# TC37XPD register map
Vendor: Infineon; Series: ATVMC; File version: 100
CPU: other r0p0, little endian, MPU, FPU, vendor SysTick, 4 interrupt priority bits
Registers are 32-bit, read-write, reset 0x0 unless marked. A register's access mark holds for its fields unless they carry their own. Offsets are from the block's base; [hi:lo] are bit positions; lines under a group give offsets from that group; {n}, {i} and the like mark numbered series; 'fields as' and 'values as' point back to an identical list.

## GTM (part 3 of 13)
Base 0xF0100000
{0x1000+0x800*i} TIM[{i}] (i=0..5) group
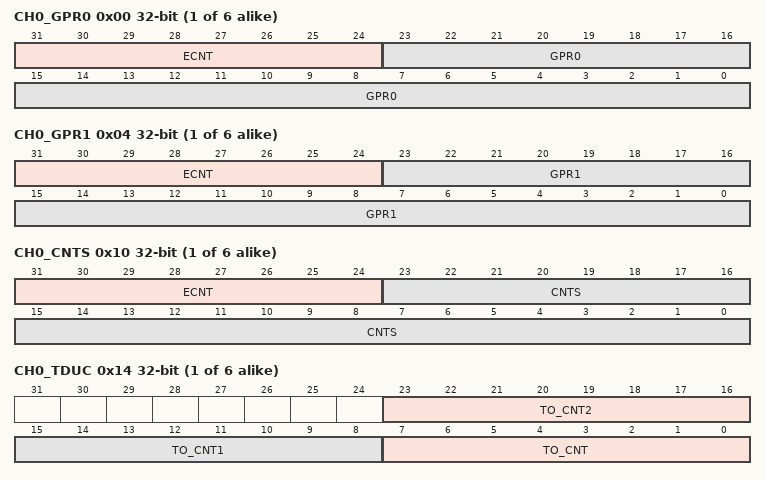
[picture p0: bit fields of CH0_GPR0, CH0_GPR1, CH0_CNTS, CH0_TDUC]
  0x00 CH0_GPR0 access per field — TIM0 Channel 7 General Purpose 0 Register resetvalue={Application Reset:0x0}
    [31:24] ECNT ro — Edge counter. The ECNT counts every incoming filtered edge rising and falling . The counter value is uneven in case of detected rising and even in case of detected falling edge. Thus the input signal level is part of the counter and can be obtained by bit 0 of ECNT .
    [23:0] GPR0 rw — Input signal characteristic parameter 0. The content of this register has different meaning for the TIM channels modes. The content directly depends on the bit fields EGPR0 SEL GPR0 SEL of register TIM i CH x CTRL . Note The content of this register can only be written in TIM channel mode TSSM.
  0x04 CH0_GPR1 access per field — TIM0 Channel 7 General Purpose 1 Register resetvalue={Application Reset:0x0}
    [31:24] ECNT ro — Edge counter. The ECNT counts every incoming filtered edge rising and falling . The counter value is uneven in case of detected rising and even in case of detected falling edge. Thus the input signal level is part of the counter and can be obtained by bit 0 of ECNT .
    [23:0] GPR1 rw — Input signal characteristic parameter 1. The content of this register has different meaning for the TIM channels modes. The content directly depends on the bit fields EGPR1 SEL GPR1 SEL of register TIM i CH x CTRL . In TBCM mode if EGPR1 SEL 1 GPR1 SEL 01 then TIM INP VAL is used as input in all other cases TIM Filter F OUT is used as input and Bits GPR1 23 8 0 The content of this register can only be written in TIM channel mode TGPS and TSSM.
  0x08 CH0_CNT ro — TIM0 Channel 7 SMU Counter Register resetvalue={Application Reset:0x0}
    [23:0] CNT — Actual SMU counter value. The meaning of this value depends on the configured mode TPWM actual duration of PWM signal.TPIM actual duration of all pulses sum of pulses .TIEM actual number of received edges.TIPM actual number of received edges.TGPS elapsed time for periodic sampling.TSSM shift data.
  0x0C CH0_ECNT ro — TIM0 Channel 7 SMU Edge Counter Register resetvalue={Application Reset:0x0}
    [15:0] ECNT — Edge counter. If TIM channel is disabled the content of ECNT gets frozen. A read will auto clear the bits 15 1 . Further read accesses to ECNT will show on Bit 0 the actual input signal value of the channel.
  0x10 CH0_CNTS access per field — TIM0 Channel 7 SMU Shadow Counter Register resetvalue={Application Reset:0x0}
    [31:24] ECNT ro — Edge counter ECNT. The ECNT counts every incoming filtered edge rising and falling . The counter value is uneven in case of detected rising and even in case of detected falling edge. Thus the input signal level is part of the counter and can be obtained by bit 0 of ECNT .
    [23:0] CNTS rw — Counter shadow register. The content of this register has different meaning for the TIM channels modes. The content depends directly on the bit field CNTS SEL of register TIM i CH x CTRL . The register TIM i CH x CNTS is only writable in TIPM TBCM TGPS and TSSM mode.
  0x14 CH0_TDUC — TIM0 Channel 7 TDU Counter Register resetvalue={Application Reset:0x0}
    [23:16] TO_CNT2 — Current Timeout value slice2 for channel x. Counter will be reset to 0x0 on TDU RESYNC condition.
    [15:8] TO_CNT1 — Current Timeout value slice1 for channel x. Counter will be reset to 0x0 on TDU RESYNC condition.
    [7:0] TO_CNT — Current Timeout value slice0 for channel x. SLICING 0b11 counter will be reset to 0X0 on TDU RESYNC condition. SLICING 0b11 counter will be loaded with TOV2 on TDU RESYNC condition.
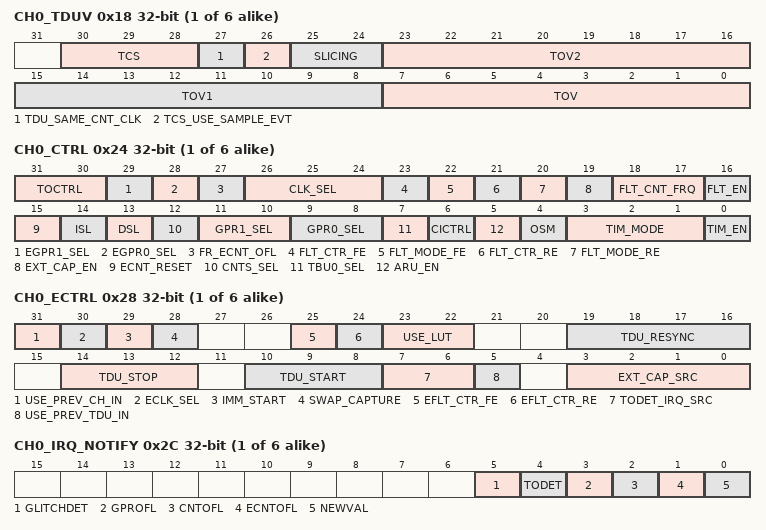
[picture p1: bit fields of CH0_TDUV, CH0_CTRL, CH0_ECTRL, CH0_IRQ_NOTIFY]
  0x18 CH0_TDUV — TIM0 Channel 7 TDU Control Register resetvalue={Application Reset:0x0}
    [30:28] TCS — Timeout Clock selection
    [27] TDU_SAME_CNT_CLK — Define clocking of TO CNT TO CNT1
    [26] TCS_USE_SAMPLE_EVT — Use tdu sample evt as Timeout Clock
    [25:24] SLICING — Cascading of counter slices. If USE LUT 0b00 USE LUT 0b00
    [23:16] TOV2 — Time out compare value slice2 for channel x. SLICING 0b11 Compare value for TO CNT2. SLICING 0b11 TOV2 operate as a shadow register for TO CNT.
    [15:8] TOV1 — Time out compare value slice1 for channel x. Compare value for TO CNT1.
    [7:0] TOV — Time out compare value slice0 for channel x. Compare value for TO CNT.
  0x1C CH0_FLT_RE — TIM0 Channel 7 Filter Parameter 0 Register resetvalue={Application Reset:0x0}
    [23:0] FLT_RE — Filter parameter for rising edge. FLT RE has different meanings in the various filter modes.Immediate edge propagation mode acceptance time for rising edgeIndividual deglitch time mode deglitch time for rising edge.
  0x20 CH0_FLT_FE — TIM0 Channel 7 Filter Parameter 1 Register resetvalue={Application Reset:0x0}
    [23:0] FLT_FE — Filter parameter for falling edge. FLT FE has different meanings in the various filter modes.Immediate edge propagation mode acceptance time for falling edge Individual deglitch time mode deglitch time for falling edge.
  0x24 CH0_CTRL — TIM0 Channel 7 Control Register resetvalue={Application Reset:0x0}
    [31:30] TOCTRL — Timeout control. It has to be mentioned that writing of TOCTRL 0 will every time stop the TDU independent of the previous state of TOCTRL.
    [29] EGPR1_SEL — Extension of GPR1 SEL bit field. Details described in GPR1 SEL bit field.
    [28] EGPR0_SEL — Extension of GPR0 SEL bit field. Details described in GPR0 SEL bit field.
    [27] FR_ECNT_OFL — Extended Edge counter overflow behavior
    [26:24] CLK_SEL — CMU clock source select for channel. If ECLK SEL 0 ECLK SEL 1
    [23] FLT_CTR_FE — Filter counter mode for falling edge. Coding see CROSSREFERENCE . Coding see Family Spec.
    [22] FLT_MODE_FE — Filter mode for falling edge. Coding see CROSSREFERENCE . Coding see Family Spec.
    [21] FLT_CTR_RE — Filter counter mode for rising edge. Coding see CROSSREFERENCE . Coding see Family Spec.
    [20] FLT_MODE_RE — Filter mode for rising edge. Coding see CROSSREFERENCE . Coding see Family Spec.
    [19] EXT_CAP_EN — Enables external capture mode. The selected TIM mode is only sensitive to external capture pulses the input event changes are ignored.
    [18:17] FLT_CNT_FRQ — Filter counter frequency select
    [16] FLT_EN — Filter enable for channel x. If the filter is disabled all filter related units including CSU are bypassed which means that the signal F IN is directly routed to signal F OUT .
    [15] ECNT_RESET — Enables resetting of counter in certain modes. If TIM MODE 0b101 TGPS TIM MODE 0b000 TPWM else ECNT counter operating in wrap around mode In TIM MODE 0b110 TSSM the bit field ECNT RESET defines the initial polarity for the shift register.
    [14] ISL — Ignore signal level. This bit is mode dependent and will have different meanings see details in the TIM Channel mode description .
    [13] DSL — Signal level control. In TIM MODE 0b110 TSSM the bit field DSL defines the shift direction. 0 B 160 160 160 160 160 Shift left 1 B 160 160 160 160 160 Shift right
    [12] CNTS_SEL — Selection for CNTS register. The functionality of the CNTS SEL is disabled in the modes TIPM TGPS and TBCM. CNTS SEL in TSSM mode selects the source signal for registered or latched shift out operation. 0 B 160 160 160 160 160 use F OUTx 1 B 160 160 160 160 160 use TIM INx
    [11:10] GPR1_SEL — Selection for GPR1 register. If EGPR1 SEL 0 EGPR1 SEL 1 If a reserved value is written to the EGPR1 SEL GPR1 SEL bit fields the hardware will use TBU TS0 input. Note In TBCM mode EGPR1 SEL 1 GPR1 SEL 01 selects TIM INP VAL as input in all other cases TIM Filter F OUT is used.
    [9:8] GPR0_SEL — Selection for GPR0 register. If EGPR0 SEL 0 EGPR0 SEL 1 If a reserved value is written to the EGPR0 SEL GPR0 SEL bit fields the hardware will use TBU TS0 input.
    [7] TBU0_SEL — TBU TS0 bits input select for TIM0 CH x GPRz z 0 1 . This bit is only applicable for TIM0.
    [6] CICTRL — Channel Input Control
    [5] ARU_EN — GPR0 and GPR1 register values routed to ARU
    [4] OSM — One shot mode. After finishing the action in one shot mode the TIM EN bit is cleared automatically.
    [3:1] TIM_MODE — TIM channel x mode. If an undefined value is written to the TIM MODE register the hardware switches automatically to TIM MODE 0b000 TPWM mode . The TIM MODE register should not be changed while the TIM channel is enabled. If the TIM channel is enabled and operating in TPWM or TPIM mode after the first valid edge defined by DSL has occurred a reconfiguration of DSL ISL TIM MODE will not change the channel behavior. Reading these bit fields after reconfiguration will show the newly configured settings but the initial channel behavior will not change. Only a disabling of the TIM channel by setting TIM EN 0 and reenabling with TIM EN 1 will change the channel operation mode.
    [0] TIM_EN — TIM channel x enable. Enabling of the channel resets the registers ECNT TIM i CH x CNT TIM i CH x GPR0 and TIM i CH x GPR1 to their reset values. After finishing the action in one shot mode the TIM EN bit is cleared automatically. Otherwise the bit must be cleared manually.
  0x28 CH0_ECTRL — TIM0 Channel 7 Extended Control Register resetvalue={Application Reset:0x0}
    [31] USE_PREV_CH_IN — Select input data source for TIM channel
    [30] ECLK_SEL — Extension of bit field CLK SEL. Details described in CLK SEL bit field of register TIM i CH x CTRL.
    [29] IMM_START — Start immediately the measurement. This bit is only applicable in TPWM and TPIM mode. Set to 0 in all other modes.
    [28] SWAP_CAPTURE — Swap point of time of capturing CNTS and GPR1. This bit is only applicable in TPWM and TPIM mode. Set to 0 in all other modes.
    [25] EFLT_CTR_FE — Extension of bit field FLT CTR FE. Details described in FLT CTR FE bit field of register TIM i CH x CTRL.
    [24] EFLT_CTR_RE — Extension of bit field FLT CTR RE. Details described in FLT CTR RE bit field of register TIM i CH x CTRL.
    [23:22] USE_LUT — Generate Filter input by lookup table
    [19:16] TDU_RESYNC — Defines condition which will resynchronize the TDU unit. Encoding see Table 160 14 and Table 160 15 .
    [14:12] TDU_STOP — Defines condition which will stop the TDU unit. Note tdu toctrl 0 event is defined as Each writing of TOCTRL 0 independent of current TOCTRL while TDU is started. This event will last 1 system clock cycle.
    [10:8] TDU_START — Defines condition which will start the TDU unit. In mode SLICING 0b11 every start restart will load the TO CNT with value TOV2. Note tdu start 000 event is defined as Each writing of TOCTRL 0 independent of current TOCTRL while TDU START 0b000 and TDU is stopped initially or stopped by TDU STOP event . This event will last 1 system clock cycle.
    [7:6] TODET_IRQ_SRC — selection of source for TODET IRQ. With TODET IRQ SRC 0b00 the ACB bit 2 will be driven by signal tdu timeout evt if TODET IRQ SRC 0b00 ACB2 will be 0.
    [5] USE_PREV_TDU_IN — Select input data source for TDU
    [3:0] EXT_CAP_SRC — Defines selected source for triggering the EXT CAPTURE functionality
  0x2C CH0_IRQ_NOTIFY — TIM0 Channel 7 Interrupt Notification Register resetvalue={Application Reset:0x0}
    [5] GLITCHDET — Glitch detected on channel x x 0...m 1 . This bit will be cleared on a CPU write access of value 1 . A read access leaves the bit unchanged.
    [4] TODET — Timeout reached for input signal of channel x. See bit 0.
    [3] GPROFL — GPR0 and GPR1 data overflow. Old data not read out before new data has arrived at input pin. See bit 0.
    [2] CNTOFL — SMU CNT counter overflow of channel x. See bit 0.
    [1] ECNTOFL — counter overflow of channel x. See bit 0.
    [0] NEWVAL — New measurement value detected by in channel x. This bit will be cleared on a CPU write access of value 1 . A read access leaves the bit unchanged.
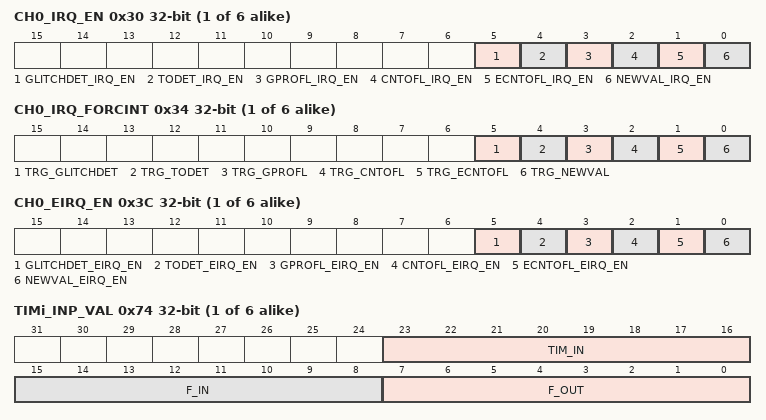
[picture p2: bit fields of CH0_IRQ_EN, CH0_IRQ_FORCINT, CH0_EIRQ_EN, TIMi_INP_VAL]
  0x30 CH0_IRQ_EN — TIM0 Channel 7 Interrupt Enable Register resetvalue={Application Reset:0x0}
    [5] GLITCHDET_IRQ_EN — TIM GLITCHDETx IRQ interrupt enable. Coding see bit 0.
    [4] TODET_IRQ_EN — TIM TODETx IRQ interrupt enable. Coding see bit 0.
    [3] GPROFL_IRQ_EN — TIM GPROFL IRQ interrupt enable. Coding see bit 0.
    [2] CNTOFL_IRQ_EN — TIM CNTOFLx IRQ interrupt enable. Coding see bit 0.
    [1] ECNTOFL_IRQ_EN — TIM ECNTOFLx IRQ interrupt enable. Coding see bit 0.
    [0] NEWVAL_IRQ_EN — TIM NEWVALx IRQ interrupt enable
  0x34 CH0_IRQ_FORCINT — TIM0 Channel 7 Force Interrupt Register resetvalue={Application Reset:0x0}
    [5] TRG_GLITCHDET — Trigger GLITCHDET bit in TIM CHx IRQ NOTIFY register by software. Coding see bit 0.
    [4] TRG_TODET — Trigger TODET bit in TIM CHx IRQ NOTIFY register by software. Coding see bit 0.
    [3] TRG_GPROFL — Trigger GPROFL bit in TIM CHx IRQ NOTIFY register by software. Coding see bit 0.
    [2] TRG_CNTOFL — Trigger CNTOFL bit in TIM CHx IRQ NOTIFY register by software. Coding see bit 0.
    [1] TRG_ECNTOFL — Trigger ECNTOFL bit in TIM CHx IRQ NOTIFY register by software. Coding see bit 0.
    [0] TRG_NEWVAL — Trigger NEWVAL bit in TIM CHx IRQ NOTIFY register by software. This bit is cleared automatically after write. This bit is write protected by bit RF PROT of register GTM CTRL.
  0x38 CH0_IRQ_MODE — TIM0 Channel 7 Interrupt Mode Configuration Register resetvalue={Application Reset:0x0}
    [1:0] IRQ_MODE — IRQ mode selection. The interrupt modes are described in CROSSREFERENCE .
  0x3C CH0_EIRQ_EN — TIM0 Channel 7 Error Interrupt Enable Register resetvalue={Application Reset:0x0}
    [5] GLITCHDET_EIRQ_EN — TIM GLITCHDETx IRQ interrupt enable. Coding see bit 0.
    [4] TODET_EIRQ_EN — TIM TODETx IRQ interrupt enable. Coding see bit 0.
    [3] GPROFL_EIRQ_EN — TIM GPROFL IRQ interrupt enable. Coding see bit 0.
    [2] CNTOFL_EIRQ_EN — TIM CNTOFLx IRQ interrupt enable. Coding see bit 0.
    [1] ECNTOFL_EIRQ_EN — TIM ECNTOFLx IRQ interrupt enable. Coding see bit 0.
    [0] NEWVAL_EIRQ_EN — TIM NEWVALx EIRQ error interrupt enable
  0x74 TIMi_INP_VAL ro — TIM0 Input Value Observation Register resetvalue={Application Reset:0x0}
    [23:16] TIM_IN — Signals after TIM input signal synchronization
    [15:8] F_IN — Signals after INPSRC selection before TIM FLT unit
    [7:0] F_OUT — Signals after TIM FLT unit
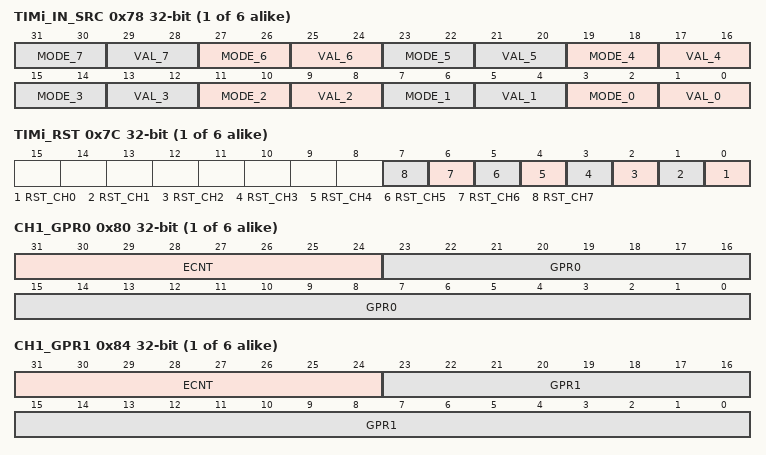
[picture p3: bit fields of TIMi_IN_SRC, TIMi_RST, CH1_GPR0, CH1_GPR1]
  0x78 TIMi_IN_SRC — TIM0 AUX IN Source Selection Register resetvalue={Application Reset:0x0}
    [4n+3:4n+2] MODE_{n} (n=0..7) — Input source to Channel 7. Multicore encoding in use MODE x 1 defines the state of the signal . Function table MODE x 1 0 VAL x 1 0 160 160 160 160 The input signal defined by bit field CICTRL of the TIM channel is used 160 160 160 160 as input source. MODE x 1 0 VAL x 1 1 160 160 160 160 The signal TIM AUX IN of the TIM channel is used as input source. MODE x 1 1 160 160 160 160 The state VAL x 1 defines the input level for the TIM channel. Any read access to a MODE x bit field will always result in a value 00 or 11 indicating current state. A modification of the state is only performed with the values 01 and 10. Writing the values 00 and 11 is always ignored.
    [4n+1:4n] VAL_{n} (n=0..7) — Value to be fed to Channel 7. Multicore encoding in use VAL x 1 defines the state of the signal . Function depends on the combination of VAL x 1 and MODE x 1 see MODE 0 description. Any read access to a VAL x bit field will always result in a value 00 or 11 indicating current state. A modification of the state is only performed with the values 01 and 10. Writing the values 00 and 11 is always ignored.
  0x7C TIMi_RST — TIM0 Global Software Reset Register resetvalue={Application Reset:0x0}
    [n] RST_CH{n} (n=0..7) — Software reset of channel 7. This bit is cleared automatically after write by CPU. The channel registers are set to their reset values and channel operation is stopped immediately. Please note that the RST field width of this register depends on the number of implemented channels m within this sub module. This register description represents a register layout for m 8.
  0x80 CH1_GPR0 access per field — TIM0 Channel 7 General Purpose 0 Register resetvalue={Application Reset:0x0}
    fields as TIM[0].CH0_GPR0
  0x84 CH1_GPR1 access per field — TIM0 Channel 7 General Purpose 1 Register resetvalue={Application Reset:0x0}
    fields as TIM[0].CH0_GPR1
  0x88 CH1_CNT ro — TIM0 Channel 7 SMU Counter Register resetvalue={Application Reset:0x0}
    fields as TIM[0].CH0_CNT
  0x8C CH1_ECNT ro — TIM0 Channel 7 SMU Edge Counter Register resetvalue={Application Reset:0x0}
    fields as TIM[0].CH0_ECNT
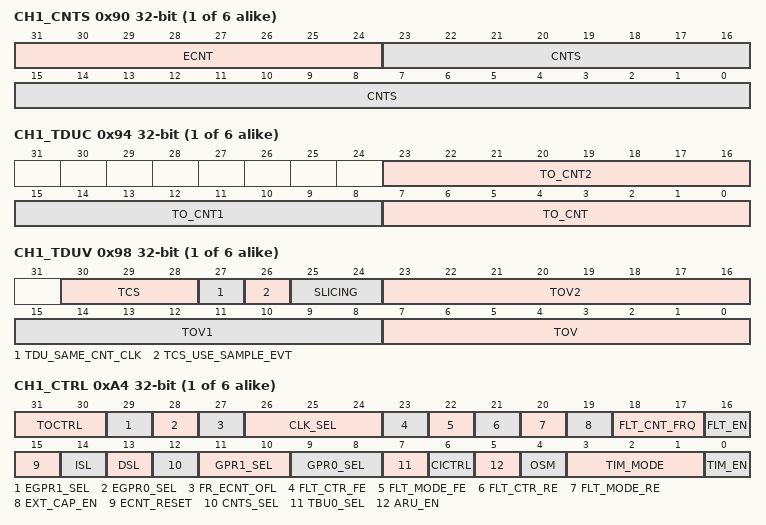
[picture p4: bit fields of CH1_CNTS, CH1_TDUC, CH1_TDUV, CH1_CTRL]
  0x90 CH1_CNTS access per field — TIM0 Channel 7 SMU Shadow Counter Register resetvalue={Application Reset:0x0}
    fields as TIM[0].CH0_CNTS
  0x94 CH1_TDUC — TIM0 Channel 7 TDU Counter Register resetvalue={Application Reset:0x0}
    fields as TIM[0].CH0_TDUC
  0x98 CH1_TDUV — TIM0 Channel 7 TDU Control Register resetvalue={Application Reset:0x0}
    fields as TIM[0].CH0_TDUV
  0x9C CH1_FLT_RE — TIM0 Channel 7 Filter Parameter 0 Register resetvalue={Application Reset:0x0}
    fields as TIM[0].CH0_FLT_RE
  0xA0 CH1_FLT_FE — TIM0 Channel 7 Filter Parameter 1 Register resetvalue={Application Reset:0x0}
    fields as TIM[0].CH0_FLT_FE
  0xA4 CH1_CTRL — TIM0 Channel 7 Control Register resetvalue={Application Reset:0x0}
    fields as TIM[0].CH0_CTRL
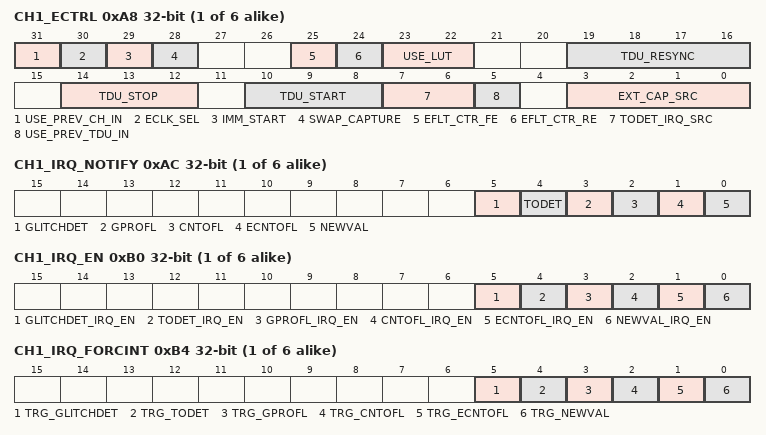
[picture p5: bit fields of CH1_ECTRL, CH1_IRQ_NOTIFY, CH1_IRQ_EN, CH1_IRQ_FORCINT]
  0xA8 CH1_ECTRL — TIM0 Channel 7 Extended Control Register resetvalue={Application Reset:0x0}
    fields as TIM[0].CH0_ECTRL
  0xAC CH1_IRQ_NOTIFY — TIM0 Channel 7 Interrupt Notification Register resetvalue={Application Reset:0x0}
    fields as TIM[0].CH0_IRQ_NOTIFY
  0xB0 CH1_IRQ_EN — TIM0 Channel 7 Interrupt Enable Register resetvalue={Application Reset:0x0}
    fields as TIM[0].CH0_IRQ_EN
  0xB4 CH1_IRQ_FORCINT — TIM0 Channel 7 Force Interrupt Register resetvalue={Application Reset:0x0}
    fields as TIM[0].CH0_IRQ_FORCINT
  0xB8 CH1_IRQ_MODE — TIM0 Channel 7 Interrupt Mode Configuration Register resetvalue={Application Reset:0x0}
    fields as TIM[0].CH0_IRQ_MODE
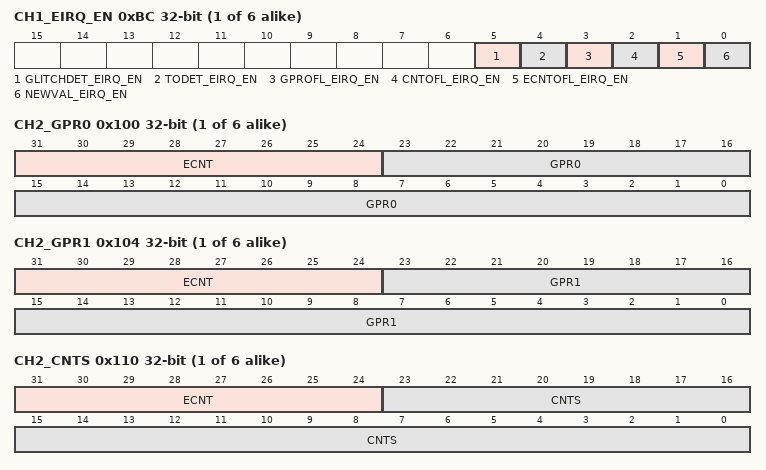
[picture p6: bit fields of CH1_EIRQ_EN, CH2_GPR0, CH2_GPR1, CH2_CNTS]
  0xBC CH1_EIRQ_EN — TIM0 Channel 7 Error Interrupt Enable Register resetvalue={Application Reset:0x0}
    fields as TIM[0].CH0_EIRQ_EN
  0x100 CH2_GPR0 access per field — TIM0 Channel 7 General Purpose 0 Register resetvalue={Application Reset:0x0}
    fields as TIM[0].CH0_GPR0
  0x104 CH2_GPR1 access per field — TIM0 Channel 7 General Purpose 1 Register resetvalue={Application Reset:0x0}
    fields as TIM[0].CH0_GPR1
  0x108 CH2_CNT ro — TIM0 Channel 7 SMU Counter Register resetvalue={Application Reset:0x0}
    fields as TIM[0].CH0_CNT
  0x10C CH2_ECNT ro — TIM0 Channel 7 SMU Edge Counter Register resetvalue={Application Reset:0x0}
    fields as TIM[0].CH0_ECNT
  0x110 CH2_CNTS access per field — TIM0 Channel 7 SMU Shadow Counter Register resetvalue={Application Reset:0x0}
    fields as TIM[0].CH0_CNTS
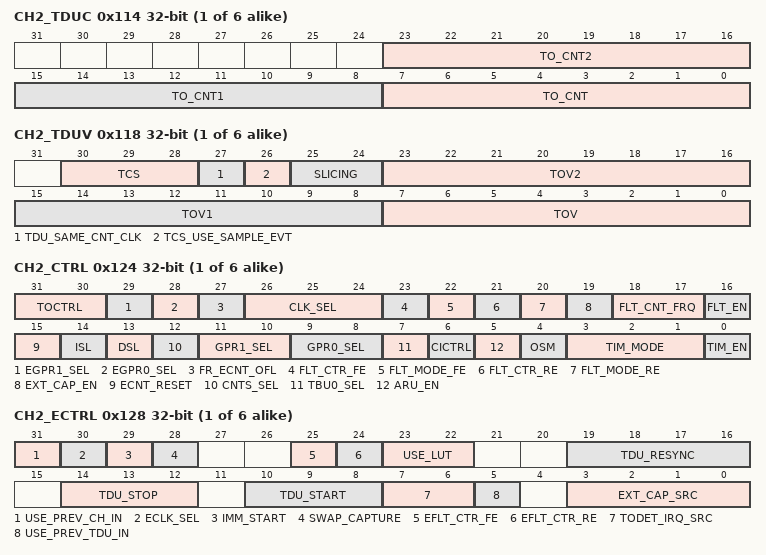
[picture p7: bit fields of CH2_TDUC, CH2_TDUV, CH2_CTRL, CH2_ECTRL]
  0x114 CH2_TDUC — TIM0 Channel 7 TDU Counter Register resetvalue={Application Reset:0x0}
    fields as TIM[0].CH0_TDUC
  0x118 CH2_TDUV — TIM0 Channel 7 TDU Control Register resetvalue={Application Reset:0x0}
    fields as TIM[0].CH0_TDUV
  0x11C CH2_FLT_RE — TIM0 Channel 7 Filter Parameter 0 Register resetvalue={Application Reset:0x0}
    fields as TIM[0].CH0_FLT_RE
  0x120 CH2_FLT_FE — TIM0 Channel 7 Filter Parameter 1 Register resetvalue={Application Reset:0x0}
    fields as TIM[0].CH0_FLT_FE
  0x124 CH2_CTRL — TIM0 Channel 7 Control Register resetvalue={Application Reset:0x0}
    fields as TIM[0].CH0_CTRL
  0x128 CH2_ECTRL — TIM0 Channel 7 Extended Control Register resetvalue={Application Reset:0x0}
    fields as TIM[0].CH0_ECTRL
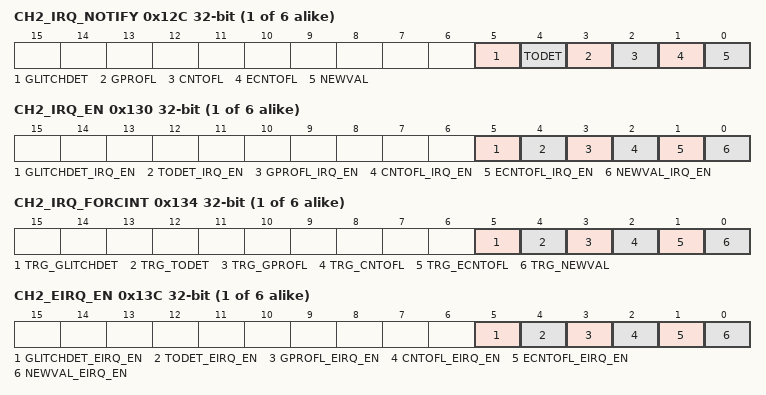
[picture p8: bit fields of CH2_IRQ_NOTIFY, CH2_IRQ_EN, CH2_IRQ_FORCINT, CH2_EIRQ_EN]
  0x12C CH2_IRQ_NOTIFY — TIM0 Channel 7 Interrupt Notification Register resetvalue={Application Reset:0x0}
    fields as TIM[0].CH0_IRQ_NOTIFY
  0x130 CH2_IRQ_EN — TIM0 Channel 7 Interrupt Enable Register resetvalue={Application Reset:0x0}
    fields as TIM[0].CH0_IRQ_EN
  0x134 CH2_IRQ_FORCINT — TIM0 Channel 7 Force Interrupt Register resetvalue={Application Reset:0x0}
    fields as TIM[0].CH0_IRQ_FORCINT
  0x138 CH2_IRQ_MODE — TIM0 Channel 7 Interrupt Mode Configuration Register resetvalue={Application Reset:0x0}
    fields as TIM[0].CH0_IRQ_MODE
  0x13C CH2_EIRQ_EN — TIM0 Channel 7 Error Interrupt Enable Register resetvalue={Application Reset:0x0}
    fields as TIM[0].CH0_EIRQ_EN
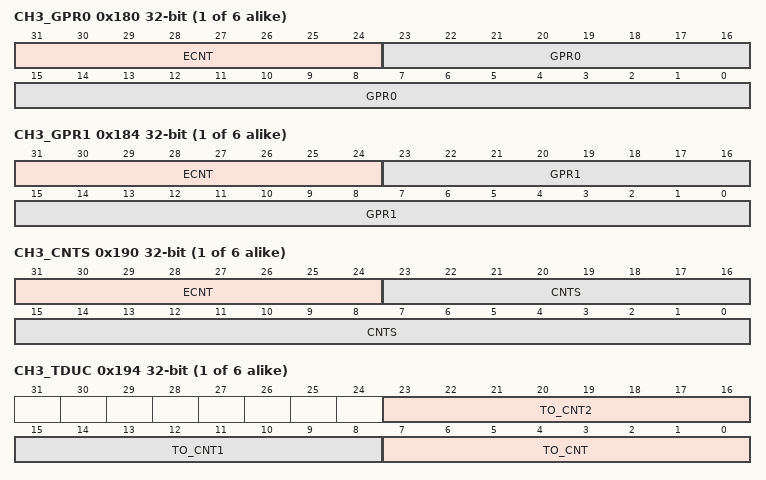
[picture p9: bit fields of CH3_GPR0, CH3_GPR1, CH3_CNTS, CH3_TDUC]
  0x180 CH3_GPR0 access per field — TIM0 Channel 7 General Purpose 0 Register resetvalue={Application Reset:0x0}
    fields as TIM[0].CH0_GPR0
  0x184 CH3_GPR1 access per field — TIM0 Channel 7 General Purpose 1 Register resetvalue={Application Reset:0x0}
    fields as TIM[0].CH0_GPR1
  0x188 CH3_CNT ro — TIM0 Channel 7 SMU Counter Register resetvalue={Application Reset:0x0}
    fields as TIM[0].CH0_CNT
  0x18C CH3_ECNT ro — TIM0 Channel 7 SMU Edge Counter Register resetvalue={Application Reset:0x0}
    fields as TIM[0].CH0_ECNT
  0x190 CH3_CNTS access per field — TIM0 Channel 7 SMU Shadow Counter Register resetvalue={Application Reset:0x0}
    fields as TIM[0].CH0_CNTS
  0x194 CH3_TDUC — TIM0 Channel 7 TDU Counter Register resetvalue={Application Reset:0x0}
    fields as TIM[0].CH0_TDUC
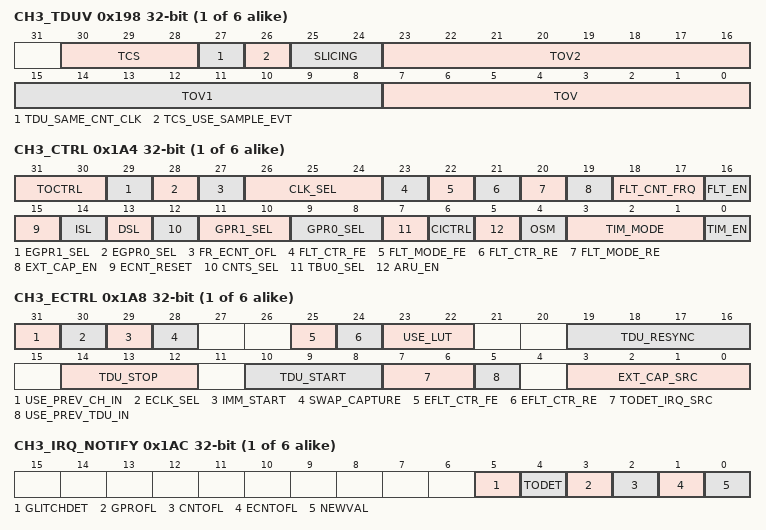
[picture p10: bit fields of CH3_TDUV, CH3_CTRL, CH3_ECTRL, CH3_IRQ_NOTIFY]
  0x198 CH3_TDUV — TIM0 Channel 7 TDU Control Register resetvalue={Application Reset:0x0}
    fields as TIM[0].CH0_TDUV
  0x19C CH3_FLT_RE — TIM0 Channel 7 Filter Parameter 0 Register resetvalue={Application Reset:0x0}
    fields as TIM[0].CH0_FLT_RE
  0x1A0 CH3_FLT_FE — TIM0 Channel 7 Filter Parameter 1 Register resetvalue={Application Reset:0x0}
    fields as TIM[0].CH0_FLT_FE
  0x1A4 CH3_CTRL — TIM0 Channel 7 Control Register resetvalue={Application Reset:0x0}
    fields as TIM[0].CH0_CTRL
  0x1A8 CH3_ECTRL — TIM0 Channel 7 Extended Control Register resetvalue={Application Reset:0x0}
    fields as TIM[0].CH0_ECTRL
  0x1AC CH3_IRQ_NOTIFY — TIM0 Channel 7 Interrupt Notification Register resetvalue={Application Reset:0x0}
    fields as TIM[0].CH0_IRQ_NOTIFY
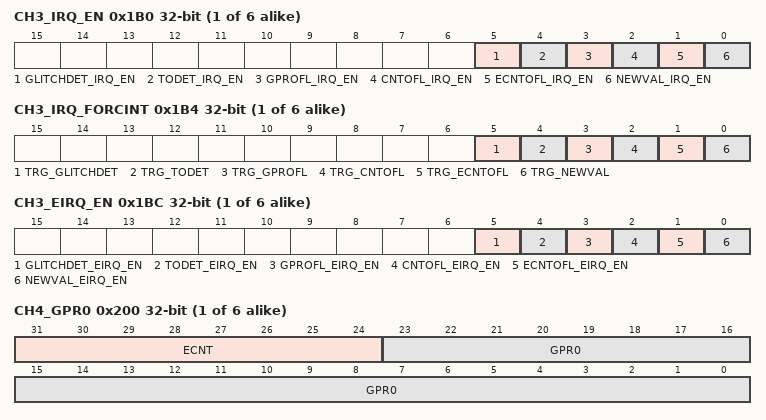
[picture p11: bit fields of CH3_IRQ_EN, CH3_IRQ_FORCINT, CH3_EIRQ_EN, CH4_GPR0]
  0x1B0 CH3_IRQ_EN — TIM0 Channel 7 Interrupt Enable Register resetvalue={Application Reset:0x0}
    fields as TIM[0].CH0_IRQ_EN
  0x1B4 CH3_IRQ_FORCINT — TIM0 Channel 7 Force Interrupt Register resetvalue={Application Reset:0x0}
    fields as TIM[0].CH0_IRQ_FORCINT
  0x1B8 CH3_IRQ_MODE — TIM0 Channel 7 Interrupt Mode Configuration Register resetvalue={Application Reset:0x0}
    fields as TIM[0].CH0_IRQ_MODE
  0x1BC CH3_EIRQ_EN — TIM0 Channel 7 Error Interrupt Enable Register resetvalue={Application Reset:0x0}
    fields as TIM[0].CH0_EIRQ_EN
  0x200 CH4_GPR0 access per field — TIM0 Channel 7 General Purpose 0 Register resetvalue={Application Reset:0x0}
    fields as TIM[0].CH0_GPR0
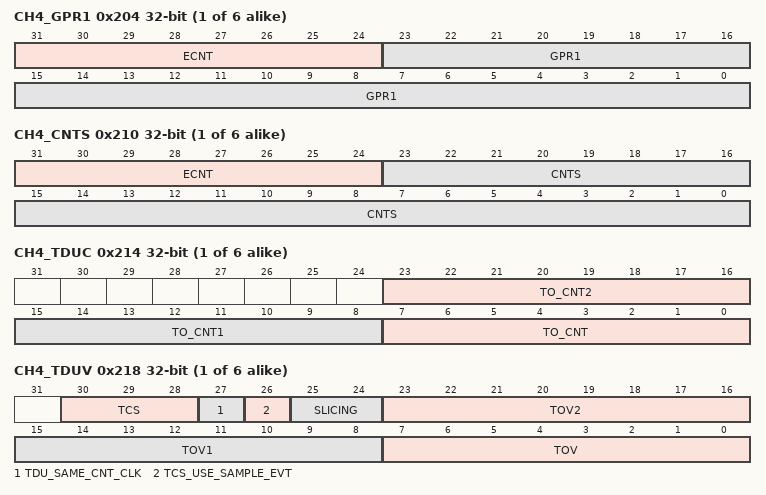
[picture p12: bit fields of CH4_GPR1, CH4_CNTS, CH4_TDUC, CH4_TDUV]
  0x204 CH4_GPR1 access per field — TIM0 Channel 7 General Purpose 1 Register resetvalue={Application Reset:0x0}
    fields as TIM[0].CH0_GPR1
  0x208 CH4_CNT ro — TIM0 Channel 7 SMU Counter Register resetvalue={Application Reset:0x0}
    fields as TIM[0].CH0_CNT
  0x20C CH4_ECNT ro — TIM0 Channel 7 SMU Edge Counter Register resetvalue={Application Reset:0x0}
    fields as TIM[0].CH0_ECNT
  0x210 CH4_CNTS access per field — TIM0 Channel 7 SMU Shadow Counter Register resetvalue={Application Reset:0x0}
    fields as TIM[0].CH0_CNTS
  0x214 CH4_TDUC — TIM0 Channel 7 TDU Counter Register resetvalue={Application Reset:0x0}
    fields as TIM[0].CH0_TDUC
  0x218 CH4_TDUV — TIM0 Channel 7 TDU Control Register resetvalue={Application Reset:0x0}
    fields as TIM[0].CH0_TDUV
  0x21C CH4_FLT_RE — TIM0 Channel 7 Filter Parameter 0 Register resetvalue={Application Reset:0x0}
    fields as TIM[0].CH0_FLT_RE
  0x220 CH4_FLT_FE — TIM0 Channel 7 Filter Parameter 1 Register resetvalue={Application Reset:0x0}
    fields as TIM[0].CH0_FLT_FE
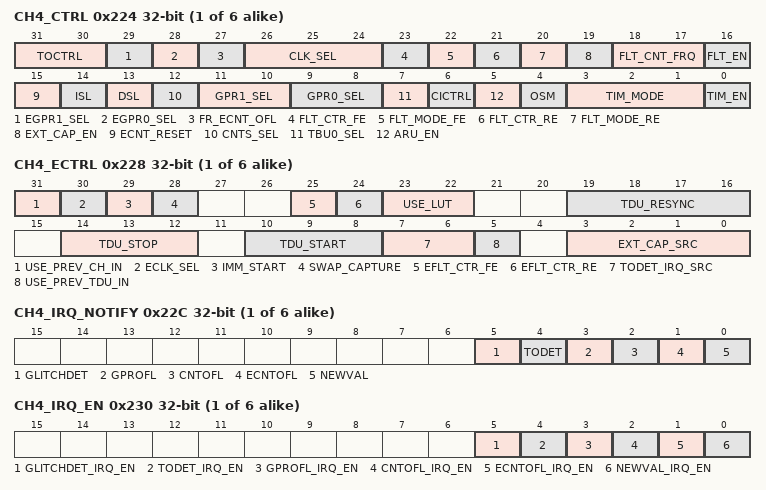
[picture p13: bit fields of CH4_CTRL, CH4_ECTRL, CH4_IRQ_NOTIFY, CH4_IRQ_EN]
  0x224 CH4_CTRL — TIM0 Channel 7 Control Register resetvalue={Application Reset:0x0}
    fields as TIM[0].CH0_CTRL
  0x228 CH4_ECTRL — TIM0 Channel 7 Extended Control Register resetvalue={Application Reset:0x0}
    fields as TIM[0].CH0_ECTRL
  0x22C CH4_IRQ_NOTIFY — TIM0 Channel 7 Interrupt Notification Register resetvalue={Application Reset:0x0}
    fields as TIM[0].CH0_IRQ_NOTIFY
  0x230 CH4_IRQ_EN — TIM0 Channel 7 Interrupt Enable Register resetvalue={Application Reset:0x0}
    fields as TIM[0].CH0_IRQ_EN
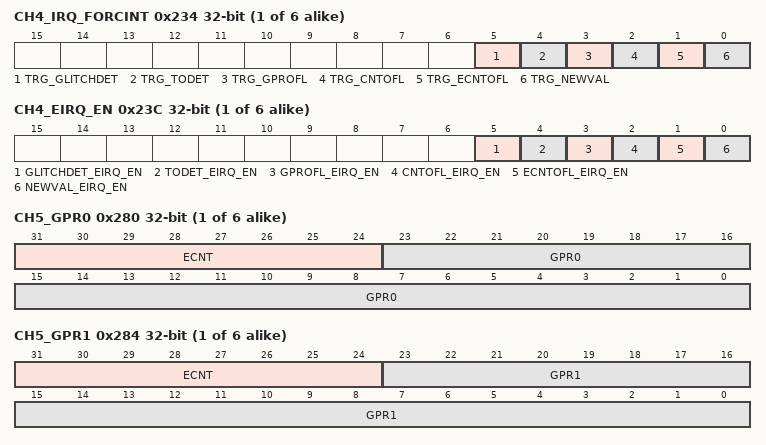
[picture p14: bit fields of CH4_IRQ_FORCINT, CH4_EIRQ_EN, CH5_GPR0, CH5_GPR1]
  0x234 CH4_IRQ_FORCINT — TIM0 Channel 7 Force Interrupt Register resetvalue={Application Reset:0x0}
    fields as TIM[0].CH0_IRQ_FORCINT
  0x238 CH4_IRQ_MODE — TIM0 Channel 7 Interrupt Mode Configuration Register resetvalue={Application Reset:0x0}
    fields as TIM[0].CH0_IRQ_MODE
  0x23C CH4_EIRQ_EN — TIM0 Channel 7 Error Interrupt Enable Register resetvalue={Application Reset:0x0}
    fields as TIM[0].CH0_EIRQ_EN
  0x280 CH5_GPR0 access per field — TIM0 Channel 7 General Purpose 0 Register resetvalue={Application Reset:0x0}
    fields as TIM[0].CH0_GPR0
  0x284 CH5_GPR1 access per field — TIM0 Channel 7 General Purpose 1 Register resetvalue={Application Reset:0x0}
    fields as TIM[0].CH0_GPR1
  0x288 CH5_CNT ro — TIM0 Channel 7 SMU Counter Register resetvalue={Application Reset:0x0}
    fields as TIM[0].CH0_CNT
  0x28C CH5_ECNT ro — TIM0 Channel 7 SMU Edge Counter Register resetvalue={Application Reset:0x0}
    fields as TIM[0].CH0_ECNT
  0x290 CH5_CNTS access per field — TIM0 Channel 7 SMU Shadow Counter Register resetvalue={Application Reset:0x0}
    fields as TIM[0].CH0_CNTS
  0x294 CH5_TDUC — TIM0 Channel 7 TDU Counter Register resetvalue={Application Reset:0x0}
    fields as TIM[0].CH0_TDUC
  0x298 CH5_TDUV — TIM0 Channel 7 TDU Control Register resetvalue={Application Reset:0x0}
    fields as TIM[0].CH0_TDUV
  0x29C CH5_FLT_RE — TIM0 Channel 7 Filter Parameter 0 Register resetvalue={Application Reset:0x0}
    fields as TIM[0].CH0_FLT_RE
  0x2A0 CH5_FLT_FE — TIM0 Channel 7 Filter Parameter 1 Register resetvalue={Application Reset:0x0}
    fields as TIM[0].CH0_FLT_FE
  0x2A4 CH5_CTRL — TIM0 Channel 7 Control Register resetvalue={Application Reset:0x0}
    fields as TIM[0].CH0_CTRL
  0x2A8 CH5_ECTRL — TIM0 Channel 7 Extended Control Register resetvalue={Application Reset:0x0}
    fields as TIM[0].CH0_ECTRL
  0x2AC CH5_IRQ_NOTIFY — TIM0 Channel 7 Interrupt Notification Register resetvalue={Application Reset:0x0}
    fields as TIM[0].CH0_IRQ_NOTIFY
  0x2B0 CH5_IRQ_EN — TIM0 Channel 7 Interrupt Enable Register resetvalue={Application Reset:0x0}
    fields as TIM[0].CH0_IRQ_EN
  0x2B4 CH5_IRQ_FORCINT — TIM0 Channel 7 Force Interrupt Register resetvalue={Application Reset:0x0}
    fields as TIM[0].CH0_IRQ_FORCINT
  0x2B8 CH5_IRQ_MODE — TIM0 Channel 7 Interrupt Mode Configuration Register resetvalue={Application Reset:0x0}
    fields as TIM[0].CH0_IRQ_MODE
  0x2BC CH5_EIRQ_EN — TIM0 Channel 7 Error Interrupt Enable Register resetvalue={Application Reset:0x0}
    fields as TIM[0].CH0_EIRQ_EN
  0x300 CH6_GPR0 access per field — TIM0 Channel 7 General Purpose 0 Register resetvalue={Application Reset:0x0}
    fields as TIM[0].CH0_GPR0
  0x304 CH6_GPR1 access per field — TIM0 Channel 7 General Purpose 1 Register resetvalue={Application Reset:0x0}
    fields as TIM[0].CH0_GPR1
  0x308 CH6_CNT ro — TIM0 Channel 7 SMU Counter Register resetvalue={Application Reset:0x0}
    fields as TIM[0].CH0_CNT
  0x30C CH6_ECNT ro — TIM0 Channel 7 SMU Edge Counter Register resetvalue={Application Reset:0x0}
    fields as TIM[0].CH0_ECNT
  0x310 CH6_CNTS access per field — TIM0 Channel 7 SMU Shadow Counter Register resetvalue={Application Reset:0x0}
    fields as TIM[0].CH0_CNTS
  0x314 CH6_TDUC — TIM0 Channel 7 TDU Counter Register resetvalue={Application Reset:0x0}
    fields as TIM[0].CH0_TDUC
  0x318 CH6_TDUV — TIM0 Channel 7 TDU Control Register resetvalue={Application Reset:0x0}
    fields as TIM[0].CH0_TDUV
  0x31C CH6_FLT_RE — TIM0 Channel 7 Filter Parameter 0 Register resetvalue={Application Reset:0x0}
    fields as TIM[0].CH0_FLT_RE
  0x320 CH6_FLT_FE — TIM0 Channel 7 Filter Parameter 1 Register resetvalue={Application Reset:0x0}
    fields as TIM[0].CH0_FLT_FE
  0x324 CH6_CTRL — TIM0 Channel 7 Control Register resetvalue={Application Reset:0x0}
    fields as TIM[0].CH0_CTRL
  0x328 CH6_ECTRL — TIM0 Channel 7 Extended Control Register resetvalue={Application Reset:0x0}
    fields as TIM[0].CH0_ECTRL
  0x32C CH6_IRQ_NOTIFY — TIM0 Channel 7 Interrupt Notification Register resetvalue={Application Reset:0x0}
    fields as TIM[0].CH0_IRQ_NOTIFY
  0x330 CH6_IRQ_EN — TIM0 Channel 7 Interrupt Enable Register resetvalue={Application Reset:0x0}
    fields as TIM[0].CH0_IRQ_EN
  0x334 CH6_IRQ_FORCINT — TIM0 Channel 7 Force Interrupt Register resetvalue={Application Reset:0x0}
    fields as TIM[0].CH0_IRQ_FORCINT
  0x338 CH6_IRQ_MODE — TIM0 Channel 7 Interrupt Mode Configuration Register resetvalue={Application Reset:0x0}
    fields as TIM[0].CH0_IRQ_MODE
  0x33C CH6_EIRQ_EN — TIM0 Channel 7 Error Interrupt Enable Register resetvalue={Application Reset:0x0}
    fields as TIM[0].CH0_EIRQ_EN
  0x380 CH7_GPR0 access per field — TIM0 Channel 7 General Purpose 0 Register resetvalue={Application Reset:0x0}
    fields as TIM[0].CH0_GPR0
  0x384 CH7_GPR1 access per field — TIM0 Channel 7 General Purpose 1 Register resetvalue={Application Reset:0x0}
    fields as TIM[0].CH0_GPR1
  0x388 CH7_CNT ro — TIM0 Channel 7 SMU Counter Register resetvalue={Application Reset:0x0}
    fields as TIM[0].CH0_CNT
  0x38C CH7_ECNT ro — TIM0 Channel 7 SMU Edge Counter Register resetvalue={Application Reset:0x0}
    fields as TIM[0].CH0_ECNT
  0x390 CH7_CNTS access per field — TIM0 Channel 7 SMU Shadow Counter Register resetvalue={Application Reset:0x0}
    fields as TIM[0].CH0_CNTS
  0x394 CH7_TDUC — TIM0 Channel 7 TDU Counter Register resetvalue={Application Reset:0x0}
    fields as TIM[0].CH0_TDUC
  0x398 CH7_TDUV — TIM0 Channel 7 TDU Control Register resetvalue={Application Reset:0x0}
    fields as TIM[0].CH0_TDUV
  0x39C CH7_FLT_RE — TIM0 Channel 7 Filter Parameter 0 Register resetvalue={Application Reset:0x0}
    fields as TIM[0].CH0_FLT_RE
  0x3A0 CH7_FLT_FE — TIM0 Channel 7 Filter Parameter 1 Register resetvalue={Application Reset:0x0}
    fields as TIM[0].CH0_FLT_FE
  0x3A4 CH7_CTRL — TIM0 Channel 7 Control Register resetvalue={Application Reset:0x0}
    fields as TIM[0].CH0_CTRL
  0x3A8 CH7_ECTRL — TIM0 Channel 7 Extended Control Register resetvalue={Application Reset:0x0}
    fields as TIM[0].CH0_ECTRL
  0x3AC CH7_IRQ_NOTIFY — TIM0 Channel 7 Interrupt Notification Register resetvalue={Application Reset:0x0}
    fields as TIM[0].CH0_IRQ_NOTIFY
  0x3B0 CH7_IRQ_EN — TIM0 Channel 7 Interrupt Enable Register resetvalue={Application Reset:0x0}
    fields as TIM[0].CH0_IRQ_EN
  0x3B4 CH7_IRQ_FORCINT — TIM0 Channel 7 Force Interrupt Register resetvalue={Application Reset:0x0}
    fields as TIM[0].CH0_IRQ_FORCINT
  0x3B8 CH7_IRQ_MODE — TIM0 Channel 7 Interrupt Mode Configuration Register resetvalue={Application Reset:0x0}
    fields as TIM[0].CH0_IRQ_MODE
  0x3BC CH7_EIRQ_EN — TIM0 Channel 7 Error Interrupt Enable Register resetvalue={Application Reset:0x0}
    fields as TIM[0].CH0_EIRQ_EN
